VERSION ""

NS_ :

BS_:

BU_: XXX DSU HCU EPS IPAS XX X

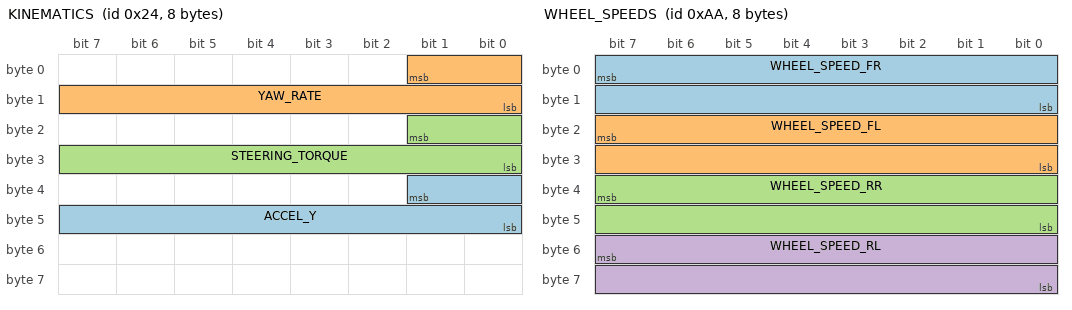
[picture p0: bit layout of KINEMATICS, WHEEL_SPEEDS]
BO_ 36 KINEMATICS: 8 XXX
 SG_ ACCEL_Y : 33|10@0+ (1,-512) [0|65535] "" XXX
 SG_ YAW_RATE : 1|10@0+ (1,-512) [0|65535] "" XXX
 SG_ STEERING_TORQUE : 17|10@0+ (1,-512) [0|65535] "" XXX

BO_ 170 WHEEL_SPEEDS: 8 XXX
 SG_ WHEEL_SPEED_FR : 7|16@0+ (0.01,-67.67) [0|250] "kph" XXX
 SG_ WHEEL_SPEED_FL : 23|16@0+ (0.01,-67.67) [0|250] "kph" XXX
 SG_ WHEEL_SPEED_RR : 39|16@0+ (0.01,-67.67) [0|250] "kph" XXX
 SG_ WHEEL_SPEED_RL : 55|16@0+ (0.01,-67.67) [0|250] "kph" XXX

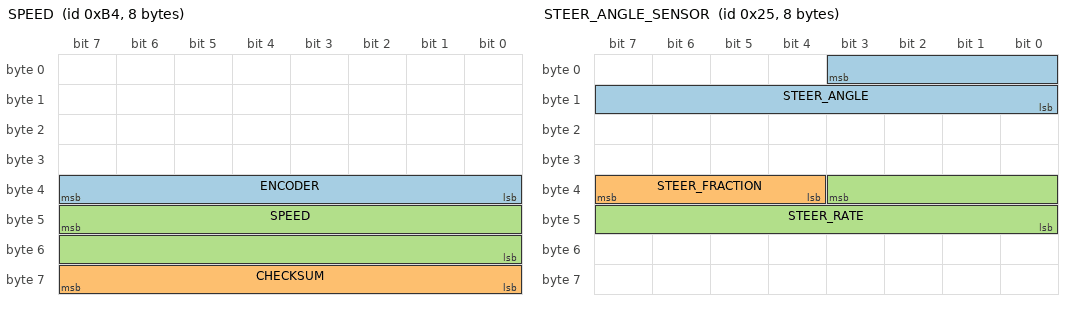
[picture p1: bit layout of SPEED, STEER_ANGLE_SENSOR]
BO_ 180 SPEED: 8 XXX
 SG_ ENCODER : 39|8@0+ (1,0) [0|255] "" XXX
 SG_ CHECKSUM : 63|8@0+ (1,0) [0|255] "" XXX
 SG_ SPEED : 47|16@0+ (0.01,0) [0|250] "kph" XXX

BO_ 560 BRAKE_MODULE2: 7 XXX
 SG_ BRAKE_PRESSED : 26|1@0+ (1,0) [0|1] "" XXX

BO_ 1556 STEERING_LEVERS: 8 XXX
 SG_ TURN_SIGNALS : 29|2@0+ (1,0) [0|3] "" XXX

BO_ 37 STEER_ANGLE_SENSOR: 8 XXX
 SG_ STEER_ANGLE : 3|12@0- (1.5,0) [-500|500] "deg" XXX
 SG_ STEER_FRACTION : 39|4@0- (0.1,0) [-0.7|0.7] "deg" XXX
 SG_ STEER_RATE : 35|12@0- (1,0) [-2000|2000] "deg/s" XXX

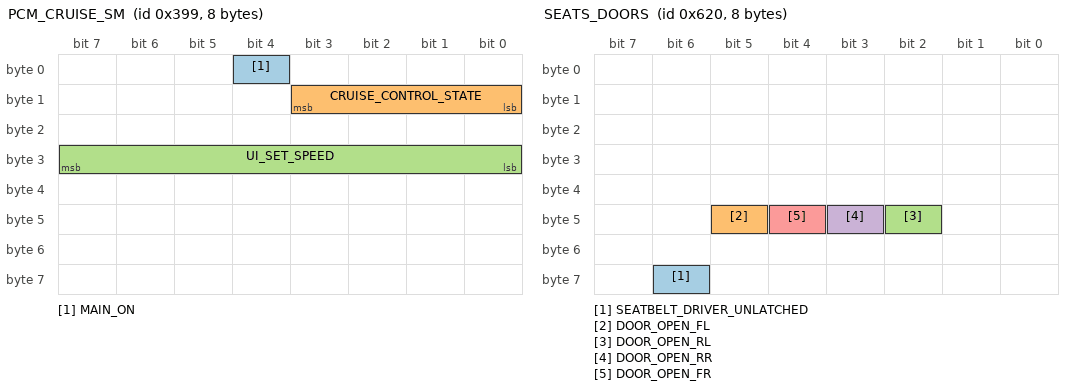
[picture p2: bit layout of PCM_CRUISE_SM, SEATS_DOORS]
BO_ 921 PCM_CRUISE_SM: 8 XXX
 SG_ MAIN_ON : 4|1@0+ (1,0) [0|1] "" XXX
 SG_ CRUISE_CONTROL_STATE : 11|4@0+ (1,0) [0|15] "" XXX
 SG_ UI_SET_SPEED : 31|8@0+ (1,0) [0|255] "" XXX

BO_ 1568 SEATS_DOORS: 8 XXX
 SG_ SEATBELT_DRIVER_UNLATCHED : 62|1@0+ (1,0) [0|1] "" XXX
 SG_ DOOR_OPEN_FL : 45|1@0+ (1,0) [0|1] "" XXX
 SG_ DOOR_OPEN_RL : 42|1@0+ (1,0) [0|1] "" XXX
 SG_ DOOR_OPEN_RR : 43|1@0+ (1,0) [0|1] "" XXX
 SG_ DOOR_OPEN_FR : 44|1@0+ (1,0) [0|1] "" XXX

BO_ 581 GAS_PEDAL: 5 XXX
 SG_ GAS_PEDAL : 23|8@0+ (0.005,0) [0|1] "" XXX

BO_ 956 GEAR_PACKET: 8 XXX
 SG_ GEAR : 13|6@0+ (1,0) [0|63] "" XXX

CM_ SG_ 36 ACCEL_Y "unit is tbd";
CM_ SG_ 36 YAW_RATE "verify";
CM_ SG_ 36 STEERING_TORQUE "does not seem the steer torque, tbd";
CM_ SG_ 466 ACCEL_NET "net acceleration produced by the system, given ACCEL_CMD, road grade and other factors";
CM_ SG_ 560 BRAKE_PRESSED "another brake pressed?";
CM_ SG_ 614 ANGLE "set to measured angle when ipas control isn't active";
CM_ SG_ 37 STEER_FRACTION "1/15th of the signal STEER_ANGLE, which is 1.5 deg; note that 0x8 is never set";
CM_ SG_ 37 STEER_RATE "factor is tbd";
CM_ SG_ 467 LOW_SPEED_LOCKOUT "in low speed lockout, system would always disengage below 28mph";
CM_ SG_ 467 SET_SPEED "43 kph are shown as 28mph, so conversion isnt perfect";
CM_ SG_ 921 UI_SET_SPEED "set speed shown in UI with user set unit";
CM_ SG_ 1042 SET_ME_1 "unclear what this is, but it's always 1 in drive traces";
CM_ SG_ 1042 REPEATED_BEEPS "recommended for fcw and other important alerts";
CM_ SG_ 581 GAS_PEDAL "it seems slightly filtered";
VAL_ 466 CRUISE_STATE 8 "active" 7 "standstill" 1 "off" ;
VAL_ 614 STATE 3 "enabled" 1 "disabled" ;
VAL_ 614 DIRECTION_CMD 3 "right" 2 "center" 1 "left" ;
VAL_ 1556 TURN_SIGNALS 3 "none" 2 "right" 1 "left" ;
VAL_ 467 LOW_SPEED_LOCKOUT 2 "low speed locked" 1 "ok" ;
VAL_ 921 CRUISE_CONTROL_STATE 2 "disabled" 11 "hold" 10 "hold_waiting_user_cmd" 6 "enabled" 5 "faulted" ;
VAL_ 1042 BARRIERS 3 "both" 2 "right" 1 "left" 0 "none" ;
VAL_ 1042 RIGHT_LINE 3 "orange" 2 "double" 1 "solid" 0 "none" ;
VAL_ 1042 LEFT_LINE 3 "orange" 2 "double" 1 "solid" 0 "none" ;
VAL_ 1042 LDA_ALERT 3 "hold with continuous beep" 2 "LDA unavailable" 1 "hold" 0 "none" ;
VAL_ 956 GEAR 0 "D" 1 "S" 8 "N" 16 "R" 32 "P" ;
CM_ "AUTOGENERATED FILE, DO NOT EDIT"
CM_ "Imported file _toyota_2017.dbc starts he";
CM_ "Imported file _toyota_2017.dbc starts her
CM_ "Imported file _toyota_2017.dbc starts her";
CM_ "Imported file _toyota_2017.dbc starts here
CM_ "Imported file _toyota_2017.dbc starts her";
CM_ "Imported file _toyota_2017.dbc starts here
CM_ "Imported file _toyota_2017.dbc starts here";
CM_ "Imported file _toyota_2017.dbc starts here"
VERSION 
CM_ "CHFFR_METRIC 37 STEER_ANGLE STEER_ANGLE 0.36 18";
CM_ "CHFFR_METRIC 37 STEER_ANGLE STEER_ANGLE 0.36 180
CM_ "toyota_rav4_hybrid_2017_pt.dbc starts here";
CM_ "toyota_rav4_hybrid_2017_pt.dbc starts here"
BO_ 550 BRAKE_MODULE: 8 XXX
SG_ BRAKE_PRESSURE : 0|9@0+ (1,0) [0|511] "" ";
